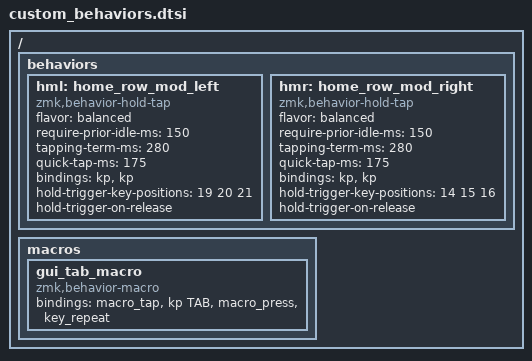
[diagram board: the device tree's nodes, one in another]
#include <dt-bindings/zmk/behaviors.h>

/ {
    behaviors {
        hml: home_row_mod_left {
            compatible = "zmk,behavior-hold-tap";
            #binding-cells = <2>;
            flavor = "balanced";
            require-prior-idle-ms = <150>;
            tapping-term-ms = <280>;
            quick-tap-ms = <175>;
            bindings = <&kp>, <&kp>;
            hold-trigger-key-positions = <19 20 21>; // List of keys on the right side of the keyboard
            hold-trigger-on-release;
        };
        hmr: home_row_mod_right {
            compatible = "zmk,behavior-hold-tap";
            #binding-cells = <2>;
            flavor = "balanced";
            require-prior-idle-ms = <150>;
            tapping-term-ms = <280>;
            quick-tap-ms = <175>;
            bindings = <&kp>, <&kp>;
            hold-trigger-key-positions =  <14 15 16>; // List of keys on the left side of the keyboard
            hold-trigger-on-release;
        };
    };
};

/ {
    macros {
        gui_tab_macro: gui_tab_macro {
            compatible = "zmk,behavior-macro";
            #binding-cells = <0>;

            // TAB einmal senden + Repeat gedrückt halten
            bindings = <
                &macro_tap   &kp TAB
                &macro_press &key_repeat
            >;

            // OPTIONAL (falls &key_repeat "klebt"):
            // bindings = <
            //     &macro_tap   &kp TAB
            //     &macro_press &key_repeat
            //     &macro_release &key_repeat
            // >;
        };
    };
};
